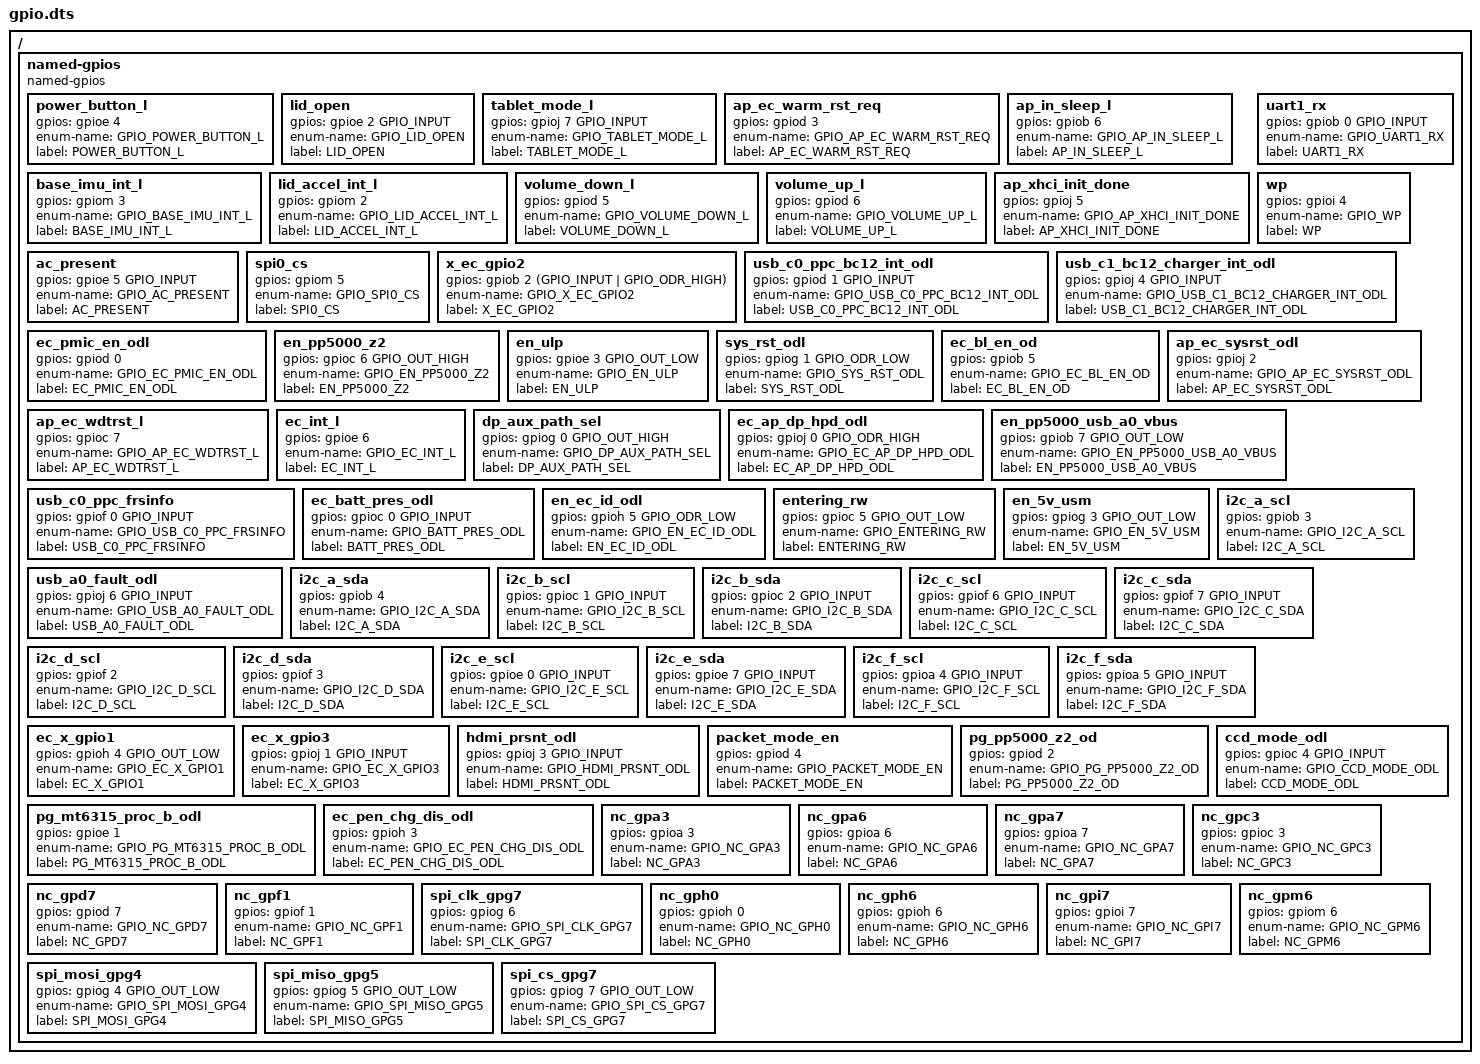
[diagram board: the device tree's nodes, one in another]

/* Copyright 2021 The Chromium OS Authors. All rights reserved.
 * Use of this source code is governed by a BSD-style license that can be
 * found in the LICENSE file.
 */

/ {
	named-gpios {
		compatible = "named-gpios";
		power_button_l: power_button_l {
			gpios = <&gpioe 4 (GPIO_INPUT | GPIO_PULL_UP)>;
			enum-name = "GPIO_POWER_BUTTON_L";
			label = "POWER_BUTTON_L";
		};
		lid_open: lid_open {
			gpios = <&gpioe 2 GPIO_INPUT>;
			enum-name = "GPIO_LID_OPEN";
			label = "LID_OPEN";
		};
		tablet_mode_l: tablet_mode_l {
			gpios = <&gpioj 7 GPIO_INPUT>;
			enum-name = "GPIO_TABLET_MODE_L";
			label = "TABLET_MODE_L";
		};
		ap_ec_warm_rst_req: ap_ec_warm_rst_req {
			gpios = <&gpiod 3 (GPIO_INPUT | GPIO_VOLTAGE_1P8)>;
			enum-name = "GPIO_AP_EC_WARM_RST_REQ";
			label = "AP_EC_WARM_RST_REQ";
		};
		ap_in_sleep_l: ap_in_sleep_l {
			gpios = <&gpiob 6 (GPIO_INPUT | GPIO_PULL_DOWN | GPIO_VOLTAGE_1P8)>;
			enum-name = "GPIO_AP_IN_SLEEP_L";
			label = "AP_IN_SLEEP_L";
		};
		base_imu_int_l: base_imu_int_l {
			gpios = <&gpiom 3 (GPIO_INPUT | GPIO_VOLTAGE_1P8)>;
			enum-name = "GPIO_BASE_IMU_INT_L";
			label = "BASE_IMU_INT_L";
		};
		lid_accel_int_l: lid_accel_int_l {
			gpios = <&gpiom 2 (GPIO_INPUT | GPIO_VOLTAGE_1P8)>;
			enum-name = "GPIO_LID_ACCEL_INT_L";
			label = "LID_ACCEL_INT_L";
		};
		volume_down_l: volume_down_l {
			gpios = <&gpiod 5 (GPIO_INPUT | GPIO_PULL_UP)>;
			enum-name = "GPIO_VOLUME_DOWN_L";
			label = "VOLUME_DOWN_L";
		};
		volume_up_l: volume_up_l {
			gpios = <&gpiod 6 (GPIO_INPUT | GPIO_PULL_UP)>;
			enum-name = "GPIO_VOLUME_UP_L";
			label = "VOLUME_UP_L";
		};
		ap_xhci_init_done: ap_xhci_init_done {
			gpios = <&gpioj 5 (GPIO_INPUT | GPIO_PULL_DOWN | GPIO_VOLTAGE_1P8)>;
			enum-name = "GPIO_AP_XHCI_INIT_DONE";
			label = "AP_XHCI_INIT_DONE";
		};
		ac_present: ac_present {
			gpios = <&gpioe 5 GPIO_INPUT>;
			enum-name = "GPIO_AC_PRESENT";
			label = "AC_PRESENT";
		};
		uart1_rx: uart1_rx {
			gpios = <&gpiob 0 GPIO_INPUT>;
			enum-name = "GPIO_UART1_RX";
			label = "UART1_RX";
		};
		wp: wp {
			gpios = <&gpioi 4 (GPIO_INPUT | GPIO_VOLTAGE_1P8)>;
			enum-name = "GPIO_WP";
			label = "WP";
		};
		spi0_cs: spi0_cs {
			gpios = <&gpiom 5 (GPIO_INPUT | GPIO_VOLTAGE_1P8)>;
			enum-name = "GPIO_SPI0_CS";
			label = "SPI0_CS";
		};
		x_ec_gpio2: x_ec_gpio2 {
			gpios = <&gpiob 2 (GPIO_INPUT | GPIO_ODR_HIGH)>;
			enum-name = "GPIO_X_EC_GPIO2";
			label = "X_EC_GPIO2";
		};
		usb_c0_ppc_bc12_int_odl: usb_c0_ppc_bc12_int_odl {
			gpios = <&gpiod 1 GPIO_INPUT>;
			enum-name = "GPIO_USB_C0_PPC_BC12_INT_ODL";
			label = "USB_C0_PPC_BC12_INT_ODL";
		};
		usb_c1_bc12_charger_int_odl: usb_c1_bc12_charger_int_odl {
			gpios = <&gpioj 4 GPIO_INPUT>;
			enum-name = "GPIO_USB_C1_BC12_CHARGER_INT_ODL";
			label = "USB_C1_BC12_CHARGER_INT_ODL";
		};
		ec_pmic_en_odl: ec_pmic_en_odl {
			gpios = <&gpiod 0 (GPIO_ODR_HIGH | GPIO_VOLTAGE_1P8)>;
			enum-name = "GPIO_EC_PMIC_EN_ODL";
			label = "EC_PMIC_EN_ODL";
		};
		en_pp5000_z2: en_pp5000_z2 {
			gpios = <&gpioc 6 GPIO_OUT_HIGH>;
			enum-name = "GPIO_EN_PP5000_Z2";
			label = "EN_PP5000_Z2";
		};
		en_ulp: en_ulp {
			gpios = <&gpioe 3 GPIO_OUT_LOW>;
			enum-name = "GPIO_EN_ULP";
			label = "EN_ULP";
		};
		sys_rst_odl: sys_rst_odl {
			gpios = <&gpiog 1 GPIO_ODR_LOW>;
			enum-name = "GPIO_SYS_RST_ODL";
			label = "SYS_RST_ODL";
		};
		ec_bl_en_od: ec_bl_en_od {
			gpios = <&gpiob 5 (GPIO_ODR_LOW | GPIO_VOLTAGE_1P8)>;
			enum-name = "GPIO_EC_BL_EN_OD";
			label = "EC_BL_EN_OD";
		};
		ap_ec_sysrst_odl: ap_ec_sysrst_odl {
			gpios = <&gpioj 2 (GPIO_INPUT | GPIO_VOLTAGE_1P8)>;
			enum-name = "GPIO_AP_EC_SYSRST_ODL";
			label = "AP_EC_SYSRST_ODL";
		};
		ap_ec_wdtrst_l: ap_ec_wdtrst_l {
			gpios = <&gpioc 7 (GPIO_INPUT | GPIO_VOLTAGE_1P8)>;
			enum-name = "GPIO_AP_EC_WDTRST_L";
			label = "AP_EC_WDTRST_L";
		};
		ec_int_l: ec_int_l {
			gpios = <&gpioe 6 (GPIO_ODR_HIGH | GPIO_VOLTAGE_1P8)>;
			enum-name = "GPIO_EC_INT_L";
			label = "EC_INT_L";
		};
		dp_aux_path_sel: dp_aux_path_sel {
			gpios = <&gpiog 0 GPIO_OUT_HIGH>;
			enum-name = "GPIO_DP_AUX_PATH_SEL";
			label = "DP_AUX_PATH_SEL";
		};
		ec_ap_dp_hpd_odl: ec_ap_dp_hpd_odl {
			gpios = <&gpioj 0 GPIO_ODR_HIGH>;
			enum-name = "GPIO_EC_AP_DP_HPD_ODL";
			label = "EC_AP_DP_HPD_ODL";
		};
		en_pp5000_usb_a0_vbus: en_pp5000_usb_a0_vbus {
			gpios = <&gpiob 7 GPIO_OUT_LOW>;
			enum-name = "GPIO_EN_PP5000_USB_A0_VBUS";
			label = "EN_PP5000_USB_A0_VBUS";
		};
		usb_c0_ppc_frsinfo: usb_c0_ppc_frsinfo {
			gpios = <&gpiof 0 GPIO_INPUT>;
			enum-name = "GPIO_USB_C0_PPC_FRSINFO";
			label = "USB_C0_PPC_FRSINFO";
		};
		ec_batt_pres_odl: ec_batt_pres_odl {
			gpios = <&gpioc 0 GPIO_INPUT>;
			enum-name = "GPIO_BATT_PRES_ODL";
			label = "BATT_PRES_ODL";
		};
		en_ec_id_odl: en_ec_id_odl {
			gpios = <&gpioh 5 GPIO_ODR_LOW>;
			enum-name = "GPIO_EN_EC_ID_ODL";
			label = "EN_EC_ID_ODL";
		};
		entering_rw: entering_rw {
			gpios = <&gpioc 5 GPIO_OUT_LOW>;
			enum-name = "GPIO_ENTERING_RW";
			label = "ENTERING_RW";
		};
		en_5v_usm: en_5v_usm {
			gpios = <&gpiog 3 GPIO_OUT_LOW>;
			enum-name = "GPIO_EN_5V_USM";
			label = "EN_5V_USM";
		};
		usb_a0_fault_odl: usb_a0_fault_odl {
			gpios = <&gpioj 6 GPIO_INPUT>;
			enum-name = "GPIO_USB_A0_FAULT_ODL";
			label = "USB_A0_FAULT_ODL";
		};
		i2c_a_scl: i2c_a_scl {
			gpios = <&gpiob 3 (GPIO_INPUT | GPIO_VOLTAGE_1P8)>;
			enum-name = "GPIO_I2C_A_SCL";
			label = "I2C_A_SCL";
		};
		i2c_a_sda: i2c_a_sda {
			gpios = <&gpiob 4 (GPIO_INPUT | GPIO_VOLTAGE_1P8)>;
			enum-name = "GPIO_I2C_A_SDA";
			label = "I2C_A_SDA";
		};
		i2c_b_scl: i2c_b_scl {
			gpios = <&gpioc 1 GPIO_INPUT>;
			enum-name = "GPIO_I2C_B_SCL";
			label = "I2C_B_SCL";
		};
		i2c_b_sda: i2c_b_sda {
			gpios = <&gpioc 2 GPIO_INPUT>;
			enum-name = "GPIO_I2C_B_SDA";
			label = "I2C_B_SDA";
		};
		i2c_c_scl: i2c_c_scl {
			gpios = <&gpiof 6 GPIO_INPUT>;
			enum-name = "GPIO_I2C_C_SCL";
			label = "I2C_C_SCL";
		};
		i2c_c_sda: i2c_c_sda {
			gpios = <&gpiof 7 GPIO_INPUT>;
			enum-name = "GPIO_I2C_C_SDA";
			label = "I2C_C_SDA";
		};
		i2c_d_scl: i2c_d_scl {
			gpios = <&gpiof 2 (GPIO_INPUT | GPIO_VOLTAGE_1P8)>;
			enum-name = "GPIO_I2C_D_SCL";
			label = "I2C_D_SCL";
		};
		i2c_d_sda: i2c_d_sda {
			gpios = <&gpiof 3 (GPIO_INPUT | GPIO_VOLTAGE_1P8)>;
			enum-name = "GPIO_I2C_D_SDA";
			label = "I2C_D_SDA";
		};
		i2c_e_scl: i2c_e_scl {
			gpios = <&gpioe 0 GPIO_INPUT>;
			enum-name = "GPIO_I2C_E_SCL";
			label = "I2C_E_SCL";
		};
		i2c_e_sda: i2c_e_sda {
			gpios = <&gpioe 7 GPIO_INPUT>;
			enum-name = "GPIO_I2C_E_SDA";
			label = "I2C_E_SDA";
		};
		i2c_f_scl: i2c_f_scl {
			gpios = <&gpioa 4 GPIO_INPUT>;
			enum-name = "GPIO_I2C_F_SCL";
			label = "I2C_F_SCL";
		};
		i2c_f_sda: i2c_f_sda {
			gpios = <&gpioa 5 GPIO_INPUT>;
			enum-name = "GPIO_I2C_F_SDA";
			label = "I2C_F_SDA";
		};
		ec_x_gpio1: ec_x_gpio1 {
			gpios = <&gpioh 4 GPIO_OUT_LOW>;
			enum-name = "GPIO_EC_X_GPIO1";
			label = "EC_X_GPIO1";
		};
		ec_x_gpio3: ec_x_gpio3 {
			gpios = <&gpioj 1 GPIO_INPUT>;
			enum-name = "GPIO_EC_X_GPIO3";
			label = "EC_X_GPIO3";
		};
		hdmi_prsnt_odl: hdmi_prsnt_odl {
			gpios = <&gpioj 3 GPIO_INPUT>;
			enum-name = "GPIO_HDMI_PRSNT_ODL";
			label = "HDMI_PRSNT_ODL";
		};
		packet_mode_en: packet_mode_en {
			gpios = <&gpiod 4 (GPIO_INPUT | GPIO_PULL_DOWN)>;
			enum-name = "GPIO_PACKET_MODE_EN";
			label = "PACKET_MODE_EN";
		};
		pg_pp5000_z2_od: pg_pp5000_z2_od {
			gpios = <&gpiod 2 (GPIO_INPUT | GPIO_PULL_DOWN)>;
			enum-name = "GPIO_PG_PP5000_Z2_OD";
			label = "PG_PP5000_Z2_OD";
		};
		pg_mt6315_proc_b_odl: pg_mt6315_proc_b_odl {
			gpios = <&gpioe 1 (GPIO_INPUT | GPIO_PULL_DOWN)>;
			enum-name = "GPIO_PG_MT6315_PROC_B_ODL";
			label = "PG_MT6315_PROC_B_ODL";
		};
		ec_pen_chg_dis_odl: ec_pen_chg_dis_odl {
			gpios = <&gpioh 3 (GPIO_INPUT | GPIO_PULL_DOWN)>;
			enum-name = "GPIO_EC_PEN_CHG_DIS_ODL";
			label = "EC_PEN_CHG_DIS_ODL";
		};
		ccd_mode_odl: ccd_mode_odl {
			gpios = <&gpioc 4 GPIO_INPUT>;
			enum-name = "GPIO_CCD_MODE_ODL";
			label = "CCD_MODE_ODL";
		};
		nc_gpa3: nc_gpa3 {
			gpios = <&gpioa 3 (GPIO_INPUT | GPIO_PULL_DOWN)>;
			enum-name = "GPIO_NC_GPA3";
			label = "NC_GPA3";
		};
		nc_gpa6: nc_gpa6 {
			gpios = <&gpioa 6 (GPIO_INPUT | GPIO_PULL_DOWN)>;
			enum-name = "GPIO_NC_GPA6";
			label = "NC_GPA6";
		};
		nc_gpa7: nc_gpa7 {
			gpios = <&gpioa 7 (GPIO_INPUT | GPIO_PULL_DOWN)>;
			enum-name = "GPIO_NC_GPA7";
			label = "NC_GPA7";
		};
		nc_gpc3: nc_gpc3 {
			gpios = <&gpioc 3 (GPIO_INPUT | GPIO_PULL_DOWN)>;
			enum-name = "GPIO_NC_GPC3";
			label = "NC_GPC3";
		};
		nc_gpd7: nc_gpd7 {
			gpios = <&gpiod 7 (GPIO_INPUT | GPIO_PULL_DOWN)>;
			enum-name = "GPIO_NC_GPD7";
			label = "NC_GPD7";
		};
		nc_gpf1: nc_gpf1 {
			gpios = <&gpiof 1 (GPIO_INPUT | GPIO_PULL_DOWN)>;
			enum-name = "GPIO_NC_GPF1";
			label = "NC_GPF1";
		};
		spi_clk_gpg7: spi_clk_gpg7 {
			gpios = <&gpiog 6 (GPIO_INPUT | GPIO_PULL_UP)>;
			enum-name = "GPIO_SPI_CLK_GPG7";
			label = "SPI_CLK_GPG7";
		};
		nc_gph0: nc_gph0 {
			gpios = <&gpioh 0 (GPIO_INPUT | GPIO_PULL_DOWN)>;
			enum-name = "GPIO_NC_GPH0";
			label = "NC_GPH0";
		};
		nc_gph6: nc_gph6 {
			gpios = <&gpioh 6 (GPIO_INPUT | GPIO_PULL_DOWN)>;
			enum-name = "GPIO_NC_GPH6";
			label = "NC_GPH6";
		};
		nc_gpi7: nc_gpi7 {
			gpios = <&gpioi 7 (GPIO_INPUT | GPIO_PULL_DOWN)>;
			enum-name = "GPIO_NC_GPI7";
			label = "NC_GPI7";
		};
		nc_gpm6: nc_gpm6 {
			gpios = <&gpiom 6 (GPIO_INPUT | GPIO_PULL_DOWN)>;
			enum-name = "GPIO_NC_GPM6";
			label = "NC_GPM6";
		};
		spi_mosi_gpg4: spi_mosi_gpg4 {
			gpios = <&gpiog 4 GPIO_OUT_LOW>;
			enum-name = "GPIO_SPI_MOSI_GPG4";
			label = "SPI_MOSI_GPG4";
		};
		spi_miso_gpg5: spi_miso_gpg5 {
			gpios = <&gpiog 5 GPIO_OUT_LOW>;
			enum-name = "GPIO_SPI_MISO_GPG5";
			label = "SPI_MISO_GPG5";
		};
		spi_cs_gpg7: spi_cs_gpg7 {
			gpios = <&gpiog 7 GPIO_OUT_LOW>;
			enum-name = "GPIO_SPI_CS_GPG7";
			label = "SPI_CS_GPG7";
		};
	};
};
